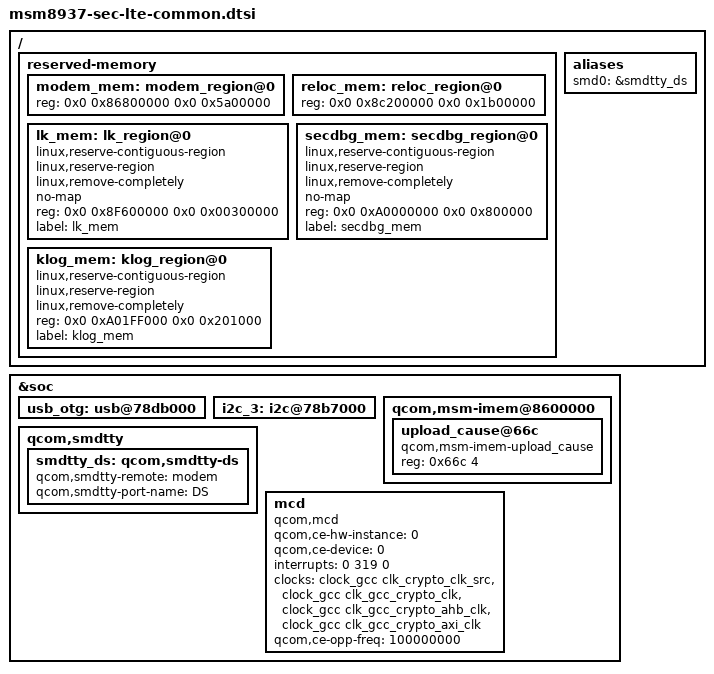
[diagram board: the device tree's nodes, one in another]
/*
 * Copyright (c) 2015, The Linux Foundation. All rights reserved.
 *
 * This program is free software; you can redistribute it and/or modify
 * it under the terms of the GNU General Public License version 2 and
 * only version 2 as published by the Free Software Foundation.
 *
 * This program is distributed in the hope that it will be useful,
 * but WITHOUT ANY WARRANTY; without even the implied warranty of
 * MERCHANTABILITY or FITNESS FOR A PARTICULAR PURPOSE.  See the
 * GNU General Public License for more details.
 */

&soc {
	usb_otg: usb@78db000 {
		/delete-property/ vbus_otg-supply;
	};
	i2c_3: i2c@78b7000 {
		/delete-property/ status;
	};
	qcom,msm-imem@8600000 {
                upload_cause@66c {
                        compatible = "qcom,msm-imem-upload_cause";
                        reg = <0x66c 4>;
                };
        };
	qcom,smdtty {
		smdtty_ds: qcom,smdtty-ds {
			qcom,smdtty-remote = "modem";
			qcom,smdtty-port-name = "DS";
		};
	};
	mcd: mcd {
		compatible = "qcom,mcd";
		qcom,ce-hw-instance = <0>;
		qcom,ce-device = <0>;
		interrupts = <0 319 0>;
		interrupt-names = "mcd_irq";
		clocks = <&clock_gcc clk_crypto_clk_src>,
			 <&clock_gcc clk_gcc_crypto_clk>,
			 <&clock_gcc clk_gcc_crypto_ahb_clk>,
			 <&clock_gcc clk_gcc_crypto_axi_clk>;
		clock-names = "core_clk_src", "core_clk",
				"iface_clk", "bus_clk";
		qcom,ce-opp-freq = <100000000>;
	};
};
/ {
	reserved-memory {
		modem_mem: modem_region@0 {
			reg = <0x0 0x86800000 0x0 0x5a00000>;
		};

		reloc_mem: reloc_region@0 {
			reg = <0x0 0x8c200000 0x0 0x1b00000>;
		};

                lk_mem: lk_region@0 {
                        linux,reserve-contiguous-region;
                        linux,reserve-region;
                        linux,remove-completely;
                        no-map;
			reg = <0x0 0x8F600000 0x0 0x00300000>;
                        label = "lk_mem";
                };

                secdbg_mem: secdbg_region@0 {
                        linux,reserve-contiguous-region;
                        linux,reserve-region;
                        linux,remove-completely;
                       	no-map;
			reg = <0x0 0xA0000000 0x0 0x800000>;
                        label = "secdbg_mem";
                };

                klog_mem: klog_region@0 {
                        linux,reserve-contiguous-region;
                        linux,reserve-region;
                        linux,remove-completely;
                        reg = <0x0 0xA01FF000 0x0 0x201000>;
                        label = "klog_mem";
                }; 
        };

	aliases {
		smd0 = &smdtty_ds;
	};
};
